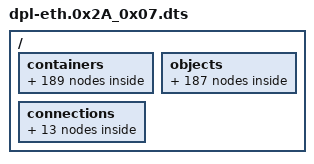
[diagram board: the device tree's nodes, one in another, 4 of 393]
/*
 * This DPL showcases one Linux configuration for SerDes 0x2a_07
 *
 * Copyright 2015 Freescale Semiconductor, Inc.
 */

/dts-v1/;
/ {
	/*****************************************************************
         * Containers
         *****************************************************************/
	containers {
		dprc@1 {
			compatible = "fsl,dprc";
			parent = "none";
			options = "DPRC_CFG_OPT_SPAWN_ALLOWED" , "DPRC_CFG_OPT_ALLOC_ALLOWED", "DPRC_CFG_OPT_IRQ_CFG_ALLOWED";

			objects {
				/* ------------- DPMACs --------------*/
				/* For SerDes 0x2a_07, 5 DPMACs are mapped
				 * on the 5 XFI ports and 8 DPMACs
				 * are mapped on the 8 SGMII ports of the PCIe
				 * Slot 4 riser card.
				 */
				obj@101 {
					obj_name = "dpmac@1";
				};
				obj@102 {
					obj_name = "dpmac@2";
				};
				obj@103 {
					obj_name = "dpmac@3";
				};
				obj@104 {
					obj_name = "dpmac@4";
				};
				obj@105 {
					obj_name = "dpmac@5";
				};

				obj@106 {
					obj_name = "dpmac@9";
				};
				obj@107 {
					obj_name = "dpmac@10";
				};
				obj@108 {
					obj_name = "dpmac@11";
				};
				obj@109 {
					obj_name = "dpmac@12";
				};
				obj@110 {
					obj_name = "dpmac@13";
				};
				obj@111 {
					obj_name = "dpmac@14";
				};
				obj@112 {
					obj_name = "dpmac@15";
				};
				obj@113 {
					obj_name = "dpmac@16";
				};

				/* ------------ DPNIs --------------*/
				obj@200 {
					obj_name="dpni@0";
				};
				obj@201 {
					obj_name="dpni@1";
				};
				obj@202 {
					obj_name="dpni@2";
				};
				obj@203 {
					obj_name="dpni@3";
				};
				obj@204 {
					obj_name="dpni@4";
				};
				obj@205 {
					obj_name="dpni@5";
				};
				obj@206 {
					obj_name="dpni@6";
				};
				obj@207 {
					obj_name="dpni@7";
				};
				obj@208 {
					obj_name="dpni@8";
				};
				obj@209 {
					obj_name="dpni@9";
				};
				obj@210 {
					obj_name="dpni@10";
				};
				obj@211 {
					obj_name="dpni@11";
				};
				obj@212 {
					obj_name="dpni@12";
				};

				/* ------------ DPBPs --------------*/
				/* Each DPNI uses one DPBP */
				obj@300 {
					obj_name="dpbp@0";
				};
				obj@301 {
					obj_name="dpbp@1";
				};
				obj@302 {
					obj_name="dpbp@2";
				};
				obj@303 {
					obj_name="dpbp@3";
				};
				obj@304 {
					obj_name="dpbp@4";
				};
				obj@305 {
					obj_name="dpbp@5";
				};
				obj@306 {
					obj_name="dpbp@6";
				};
				obj@307 {
					obj_name="dpbp@7";
				};
				obj@308 {
					obj_name="dpbp@8";
				};
				obj@309 {
					obj_name="dpbp@9";
				};
				obj@310 {
					obj_name="dpbp@10";
				};
				obj@311 {
					obj_name="dpbp@11";
				};
				obj@312 {
					obj_name="dpbp@12";
				};


				/* ------------ DPMCPs --------------*/
				/* Ethernet DPMCPs:
				*  One for every DPNI, one for every DPMAC, then
				*  one more for DPIO.
				*
				*  Next: DPRC and restool, VFIO and possibly
				*  others from the kernel have DPMCP requirements.
				*  We'll just add a slack of 10 MCPs.
				*/
				obj@501 {
					obj_name="dpmcp@1";
				};
				obj@502 {
					obj_name="dpmcp@2";
				};
				obj@503 {
					obj_name="dpmcp@3";
				};
				obj@504 {
					obj_name="dpmcp@4";
				};
				obj@505 {
					obj_name="dpmcp@5";
				};
				obj@506 {
					obj_name="dpmcp@6";
				};
				obj@507 {
					obj_name="dpmcp@7";
				};
				obj@508 {
					obj_name="dpmcp@8";
				};
				obj@509 {
					obj_name="dpmcp@9";
				};
				obj@510 {
					obj_name="dpmcp@10";
				};
				obj@511 {
					obj_name="dpmcp@11";
				};
				obj@512 {
					obj_name="dpmcp@12";
				};
				obj@513 {
					obj_name="dpmcp@13";
				};
				obj@514 {
					obj_name="dpmcp@14";
				};
				obj@515 {
					obj_name="dpmcp@15";
				};
				obj@516 {
					obj_name="dpmcp@16";
				};
				obj@517 {
					obj_name="dpmcp@17";
				};
				obj@518 {
					obj_name="dpmcp@18";
				};
				obj@519 {
					obj_name="dpmcp@19";
				};
				obj@520 {
					obj_name="dpmcp@20";
				};
				obj@521 {
					obj_name="dpmcp@21";
				};
				obj@522 {
					obj_name="dpmcp@22";
				};
				obj@523 {
					obj_name="dpmcp@23";
				};
				obj@524 {
					obj_name="dpmcp@24";
				};
				obj@525 {
					obj_name="dpmcp@25";
				};
				obj@526 {
					obj_name="dpmcp@26";
				};
				obj@527 {
					obj_name="dpmcp@27";
				};
				obj@528 {
					obj_name="dpmcp@28";
				};
				obj@529 {
					obj_name="dpmcp@29";
				};
				obj@530 {
					obj_name="dpmcp@30";
				};
				obj@531 {
					obj_name="dpmcp@31";
				};
				obj@532 {
					obj_name="dpmcp@32";
				};
				obj@533 {
					obj_name="dpmcp@33";
				};
				obj@534 {
					obj_name="dpmcp@34";
				};
				obj@535 {
					obj_name="dpmcp@35";
				};
				obj@536 {
					obj_name="dpmcp@36";
				};

				/* ------------ DPIOs --------------*/
				/* One DPIO for each online CPU. This is a
				 * maximal configuration.
				 */
				obj@400 {
					obj_name="dpio@0";
				};
				obj@401 {
					obj_name="dpio@1";
				};
				obj@402 {
					obj_name="dpio@2";
				};
				obj@403 {
					obj_name="dpio@3";
				};
				obj@404 {
					obj_name="dpio@4";
				};
				obj@405 {
					obj_name="dpio@5";
				};
				obj@406 {
					obj_name="dpio@6";
				};
				obj@407 {
					obj_name="dpio@7";
				};

				/* ------------ DPCONs --------------*/
				/* Used by DPNIs in Linux for CDAN-based dequeueing.
				 * Ideally, there should be one DPCON per {DPNIxDPIO}
				 * combination.
				 */
				obj@600 {
					obj_name="dpcon@0";
				};
				obj@601 {
					obj_name="dpcon@1";
				};
				obj@602 {
					obj_name="dpcon@2";
				};
				obj@603 {
					obj_name="dpcon@3";
				};
				obj@604 {
					obj_name="dpcon@4";
				};
				obj@605 {
					obj_name="dpcon@5";
				};
				obj@606 {
					obj_name="dpcon@6";
				};
				obj@607 {
					obj_name="dpcon@7";
				};
				obj@608 {
					obj_name="dpcon@8";
				};
				obj@609 {
					obj_name="dpcon@9";
				};
				obj@610 {
					obj_name="dpcon@10";
				};
				obj@611 {
					obj_name="dpcon@11";
				};
				obj@612 {
					obj_name="dpcon@12";
				};
				obj@613 {
					obj_name="dpcon@13";
				};
				obj@614 {
					obj_name="dpcon@14";
				};
				obj@615 {
					obj_name="dpcon@15";
				};
				obj@616 {
					obj_name="dpcon@16";
				};
				obj@617 {
					obj_name="dpcon@17";
				};
				obj@618 {
					obj_name="dpcon@18";
				};
				obj@619 {
					obj_name="dpcon@19";
				};
				obj@620 {
					obj_name="dpcon@20";
				};
				obj@621 {
					obj_name="dpcon@21";
				};
				obj@622 {
					obj_name="dpcon@22";
				};
				obj@623 {
					obj_name="dpcon@23";
				};
				obj@624 {
					obj_name="dpcon@24";
				};
				obj@625 {
					obj_name="dpcon@25";
				};
				obj@626 {
					obj_name="dpcon@26";
				};
				obj@627 {
					obj_name="dpcon@27";
				};
				obj@628 {
					obj_name="dpcon@28";
				};
				obj@629 {
					obj_name="dpcon@29";
				};
				obj@630 {
					obj_name="dpcon@30";
				};
				obj@631 {
					obj_name="dpcon@31";
				};
				obj@632 {
					obj_name="dpcon@32";
				};
				obj@633 {
					obj_name="dpcon@33";
				};
				obj@634 {
					obj_name="dpcon@34";
				};
				obj@635 {
					obj_name="dpcon@35";
				};
				obj@636 {
					obj_name="dpcon@36";
				};
				obj@637 {
					obj_name="dpcon@37";
				};
				obj@638 {
					obj_name="dpcon@38";
				};
				obj@639 {
					obj_name="dpcon@39";
				};
				obj@640 {
					obj_name="dpcon@40";
				};
				obj@641 {
					obj_name="dpcon@41";
				};
				obj@642 {
					obj_name="dpcon@42";
				};
				obj@643 {
					obj_name="dpcon@43";
				};
				obj@644 {
					obj_name="dpcon@44";
				};
				obj@645 {
					obj_name="dpcon@45";
				};
				obj@646 {
					obj_name="dpcon@46";
				};
				obj@647 {
					obj_name="dpcon@47";
				};
				obj@648 {
					obj_name="dpcon@48";
				};
				obj@649 {
					obj_name="dpcon@49";
				};
				obj@650 {
					obj_name="dpcon@50";
				};
				obj@651 {
					obj_name="dpcon@51";
				};
				obj@652 {
					obj_name="dpcon@52";
				};
				obj@653 {
					obj_name="dpcon@53";
				};
				obj@654 {
					obj_name="dpcon@54";
				};
				obj@655 {
					obj_name="dpcon@55";
				};
				obj@656 {
					obj_name="dpcon@56";
				};
				obj@657 {
					obj_name="dpcon@57";
				};
				obj@658 {
					obj_name="dpcon@58";
				};
				obj@659 {
					obj_name="dpcon@59";
				};
				obj@660 {
					obj_name="dpcon@60";
				};
				obj@661 {
					obj_name="dpcon@61";
				};
				obj@662 {
					obj_name="dpcon@62";
				};
				obj@663 {
					obj_name="dpcon@63";
				};
				obj@664 {
					obj_name="dpcon@64";
				};
				obj@665 {
					obj_name="dpcon@65";
				};
				obj@666 {
					obj_name="dpcon@66";
				};
				obj@667 {
					obj_name="dpcon@67";
				};
				obj@668 {
					obj_name="dpcon@68";
				};
				obj@669 {
					obj_name="dpcon@69";
				};
				obj@670 {
					obj_name="dpcon@70";
				};
				obj@671 {
					obj_name="dpcon@71";
				};
				obj@672 {
					obj_name="dpcon@72";
				};
				obj@673 {
					obj_name="dpcon@73";
				};
				obj@674 {
					obj_name="dpcon@74";
				};
				obj@675 {
					obj_name="dpcon@75";
				};
				obj@676 {
					obj_name="dpcon@76";
				};
				obj@677 {
					obj_name="dpcon@77";
				};
				obj@678 {
					obj_name="dpcon@78";
				};
				obj@679 {
					obj_name="dpcon@79";
				};
				obj@680 {
					obj_name="dpcon@80";
				};
				obj@681 {
					obj_name="dpcon@81";
				};
				obj@682 {
					obj_name="dpcon@82";
				};
				obj@683 {
					obj_name="dpcon@83";
				};
				obj@684 {
					obj_name="dpcon@84";
				};
				obj@685 {
					obj_name="dpcon@85";
				};
				obj@686 {
					obj_name="dpcon@86";
				};
				obj@687 {
					obj_name="dpcon@87";
				};
				obj@688 {
					obj_name="dpcon@88";
				};
				obj@689 {
					obj_name="dpcon@89";
				};
				obj@690 {
					obj_name="dpcon@90";
				};
				obj@691 {
					obj_name="dpcon@91";
				};
				obj@692 {
					obj_name="dpcon@92";
				};
				obj@693 {
					obj_name="dpcon@93";
				};
				obj@694 {
					obj_name="dpcon@94";
				};
				obj@695 {
					obj_name="dpcon@95";
				};
				obj@696 {
					obj_name="dpcon@96";
				};
				obj@697 {
					obj_name="dpcon@97";
				};
				obj@698 {
					obj_name="dpcon@98";
				};
				obj@699 {
					obj_name="dpcon@99";
				};
				obj@700 {
					obj_name="dpcon@100";
				};
				obj@701 {
					obj_name="dpcon@101";
				};
				obj@702 {
					obj_name="dpcon@102";
				};
				obj@703 {
					obj_name="dpcon@103";
				};
			};
		};
	};

	/*****************************************************************
         * Objects
         *****************************************************************/
	objects {

		/* ------------ DPBP --------------*/
		dpbp@0 {
			compatible="fsl,dpbp";
		};
		dpbp@1 {
			compatible="fsl,dpbp";
		};
		dpbp@2 {
			compatible="fsl,dpbp";
		};
		dpbp@3 {
			compatible="fsl,dpbp";
		};
		dpbp@4 {
			compatible="fsl,dpbp";
		};
		dpbp@5 {
			compatible="fsl,dpbp";
		};
		dpbp@6 {
			compatible="fsl,dpbp";
		};
		dpbp@7 {
			compatible="fsl,dpbp";
		};
		dpbp@8 {
			compatible="fsl,dpbp";
		};
		dpbp@9 {
			compatible="fsl,dpbp";
		};
		dpbp@10 {
			compatible="fsl,dpbp";
		};
		dpbp@11 {
			compatible="fsl,dpbp";
		};
		dpbp@12 {
			compatible="fsl,dpbp";
		};

		/* ------------ DPIO --------------*/
		dpio@0 {
			compatible="fsl,dpio";
			channel_mode="DPIO_LOCAL_CHANNEL";
			num_priorities=<8>;
		};
		dpio@1 {
			compatible="fsl,dpio";
			channel_mode="DPIO_LOCAL_CHANNEL";
			num_priorities=<8>;
		};
		dpio@2 {
			compatible="fsl,dpio";
			channel_mode="DPIO_LOCAL_CHANNEL";
			num_priorities=<8>;
		};
		dpio@3 {
			compatible="fsl,dpio";
			channel_mode="DPIO_LOCAL_CHANNEL";
			num_priorities=<8>;
		};
		dpio@4 {
			compatible="fsl,dpio";
			channel_mode="DPIO_LOCAL_CHANNEL";
			num_priorities=<8>;
		};
		dpio@5 {
			compatible="fsl,dpio";
			channel_mode="DPIO_LOCAL_CHANNEL";
			num_priorities=<8>;
		};
		dpio@6 {
			compatible="fsl,dpio";
			channel_mode="DPIO_LOCAL_CHANNEL";
			num_priorities=<8>;
		};
		dpio@7 {
			compatible="fsl,dpio";
			channel_mode="DPIO_LOCAL_CHANNEL";
			num_priorities=<8>;
		};

		/* ------------ DPCON --------------*/
		/* Use 2-WQ channels to accomodate the many DPNI needs */
		dpcon@0 {
			compatible="fsl,dpcon";
			num_priorities=<2>;
		};
		dpcon@1 {
			compatible="fsl,dpcon";
			num_priorities=<2>;
		};
		dpcon@2 {
			compatible="fsl,dpcon";
			num_priorities=<2>;
		};
		dpcon@3 {
			compatible="fsl,dpcon";
			num_priorities=<2>;
		};
		dpcon@4 {
			compatible="fsl,dpcon";
			num_priorities=<2>;
		};
		dpcon@5 {
			compatible="fsl,dpcon";
			num_priorities=<2>;
		};
		dpcon@6 {
			compatible="fsl,dpcon";
			num_priorities=<2>;
		};
		dpcon@7 {
			compatible="fsl,dpcon";
			num_priorities=<2>;
		};
		dpcon@8 {
			compatible="fsl,dpcon";
			num_priorities=<2>;
		};
		dpcon@9 {
			compatible="fsl,dpcon";
			num_priorities=<2>;
		};
		dpcon@10 {
			compatible="fsl,dpcon";
			num_priorities=<2>;
		};
		dpcon@11 {
			compatible="fsl,dpcon";
			num_priorities=<2>;
		};
		dpcon@12 {
			compatible="fsl,dpcon";
			num_priorities=<2>;
		};
		dpcon@13 {
			compatible="fsl,dpcon";
			num_priorities=<2>;
		};
		dpcon@14 {
			compatible="fsl,dpcon";
			num_priorities=<2>;
		};
		dpcon@15 {
			compatible="fsl,dpcon";
			num_priorities=<2>;
		};
		dpcon@16 {
			compatible="fsl,dpcon";
			num_priorities=<2>;
		};
		dpcon@17 {
			compatible="fsl,dpcon";
			num_priorities=<2>;
		};
		dpcon@18 {
			compatible="fsl,dpcon";
			num_priorities=<2>;
		};
		dpcon@19 {
			compatible="fsl,dpcon";
			num_priorities=<2>;
		};
		dpcon@20 {
			compatible="fsl,dpcon";
			num_priorities=<2>;
		};
		dpcon@21 {
			compatible="fsl,dpcon";
			num_priorities=<2>;
		};
		dpcon@22 {
			compatible="fsl,dpcon";
			num_priorities=<2>;
		};
		dpcon@23 {
			compatible="fsl,dpcon";
			num_priorities=<2>;
		};
		dpcon@24 {
			compatible="fsl,dpcon";
			num_priorities=<2>;
		};
		dpcon@25 {
			compatible="fsl,dpcon";
			num_priorities=<2>;
		};
		dpcon@26 {
			compatible="fsl,dpcon";
			num_priorities=<2>;
		};
		dpcon@27 {
			compatible="fsl,dpcon";
			num_priorities=<2>;
		};
		dpcon@28 {
			compatible="fsl,dpcon";
			num_priorities=<2>;
		};
		dpcon@29 {
			compatible="fsl,dpcon";
			num_priorities=<2>;
		};
		dpcon@30 {
			compatible="fsl,dpcon";
			num_priorities=<2>;
		};
		dpcon@31 {
			compatible="fsl,dpcon";
			num_priorities=<2>;
		};
		dpcon@32 {
			compatible="fsl,dpcon";
			num_priorities=<2>;
		};
		dpcon@33 {
			compatible="fsl,dpcon";
			num_priorities=<2>;
		};
		dpcon@34 {
			compatible="fsl,dpcon";
			num_priorities=<2>;
		};
		dpcon@35 {
			compatible="fsl,dpcon";
			num_priorities=<2>;
		};
		dpcon@36 {
			compatible="fsl,dpcon";
			num_priorities=<2>;
		};
		dpcon@37 {
			compatible="fsl,dpcon";
			num_priorities=<2>;
		};
		dpcon@38 {
			compatible="fsl,dpcon";
			num_priorities=<2>;
		};
		dpcon@39 {
			compatible="fsl,dpcon";
			num_priorities=<2>;
		};
		dpcon@40 {
			compatible="fsl,dpcon";
			num_priorities=<2>;
		};
		dpcon@41 {
			compatible="fsl,dpcon";
			num_priorities=<2>;
		};
		dpcon@42 {
			compatible="fsl,dpcon";
			num_priorities=<2>;
		};
		dpcon@43 {
			compatible="fsl,dpcon";
			num_priorities=<2>;
		};
		dpcon@44 {
			compatible="fsl,dpcon";
			num_priorities=<2>;
		};
		dpcon@45 {
			compatible="fsl,dpcon";
			num_priorities=<2>;
		};
		dpcon@46 {
			compatible="fsl,dpcon";
			num_priorities=<2>;
		};
		dpcon@47 {
			compatible="fsl,dpcon";
			num_priorities=<2>;
		};
		dpcon@48 {
			compatible="fsl,dpcon";
			num_priorities=<2>;
		};
		dpcon@49 {
			compatible="fsl,dpcon";
			num_priorities=<2>;
		};
		dpcon@50 {
			compatible="fsl,dpcon";
			num_priorities=<2>;
		};
		dpcon@51 {
			compatible="fsl,dpcon";
			num_priorities=<2>;
		};
		dpcon@52 {
			compatible="fsl,dpcon";
			num_priorities=<2>;
		};
		dpcon@53 {
			compatible="fsl,dpcon";
			num_priorities=<2>;
		};
		dpcon@54 {
			compatible="fsl,dpcon";
			num_priorities=<2>;
		};
		dpcon@55 {
			compatible="fsl,dpcon";
			num_priorities=<2>;
		};
		dpcon@56 {
			compatible="fsl,dpcon";
			num_priorities=<2>;
		};
		dpcon@57 {
			compatible="fsl,dpcon";
			num_priorities=<2>;
		};
		dpcon@58 {
			compatible="fsl,dpcon";
			num_priorities=<2>;
		};
		dpcon@59 {
			compatible="fsl,dpcon";
			num_priorities=<2>;
		};
		dpcon@60 {
			compatible="fsl,dpcon";
			num_priorities=<2>;
		};
		dpcon@61 {
			compatible="fsl,dpcon";
			num_priorities=<2>;
		};
		dpcon@62 {
			compatible="fsl,dpcon";
			num_priorities=<2>;
		};
		dpcon@63 {
			compatible="fsl,dpcon";
			num_priorities=<2>;
		};
		dpcon@64 {
			compatible="fsl,dpcon";
			num_priorities=<2>;
		};
		dpcon@65 {
			compatible="fsl,dpcon";
			num_priorities=<2>;
		};
		dpcon@66 {
			compatible="fsl,dpcon";
			num_priorities=<2>;
		};
		dpcon@67 {
			compatible="fsl,dpcon";
			num_priorities=<2>;
		};
		dpcon@68 {
			compatible="fsl,dpcon";
			num_priorities=<2>;
		};
		dpcon@69 {
			compatible="fsl,dpcon";
			num_priorities=<2>;
		};
		dpcon@70 {
			compatible="fsl,dpcon";
			num_priorities=<2>;
		};
		dpcon@71 {
			compatible="fsl,dpcon";
			num_priorities=<2>;
		};
		dpcon@72 {
			compatible="fsl,dpcon";
			num_priorities=<2>;
		};
		dpcon@73 {
			compatible="fsl,dpcon";
			num_priorities=<2>;
		};
		dpcon@74 {
			compatible="fsl,dpcon";
			num_priorities=<2>;
		};
		dpcon@75 {
			compatible="fsl,dpcon";
			num_priorities=<2>;
		};
		dpcon@76 {
			compatible="fsl,dpcon";
			num_priorities=<2>;
		};
		dpcon@77 {
			compatible="fsl,dpcon";
			num_priorities=<2>;
		};
		dpcon@78 {
			compatible="fsl,dpcon";
			num_priorities=<2>;
		};
		dpcon@79 {
			compatible="fsl,dpcon";
			num_priorities=<2>;
		};
		dpcon@80 {
			compatible="fsl,dpcon";
			num_priorities=<2>;
		};
		dpcon@81 {
			compatible="fsl,dpcon";
			num_priorities=<2>;
		};
		dpcon@82 {
			compatible="fsl,dpcon";
			num_priorities=<2>;
		};
		dpcon@83 {
			compatible="fsl,dpcon";
			num_priorities=<2>;
		};
		dpcon@84 {
			compatible="fsl,dpcon";
			num_priorities=<2>;
		};
		dpcon@85 {
			compatible="fsl,dpcon";
			num_priorities=<2>;
		};
		dpcon@86 {
			compatible="fsl,dpcon";
			num_priorities=<2>;
		};
		dpcon@87 {
			compatible="fsl,dpcon";
			num_priorities=<2>;
		};
		dpcon@88 {
			compatible="fsl,dpcon";
			num_priorities=<2>;
		};
		dpcon@89 {
			compatible="fsl,dpcon";
			num_priorities=<2>;
		};
		dpcon@90 {
			compatible="fsl,dpcon";
			num_priorities=<2>;
		};
		dpcon@91 {
			compatible="fsl,dpcon";
			num_priorities=<2>;
		};
		dpcon@92 {
			compatible="fsl,dpcon";
			num_priorities=<2>;
		};
		dpcon@93 {
			compatible="fsl,dpcon";
			num_priorities=<2>;
		};
		dpcon@94 {
			compatible="fsl,dpcon";
			num_priorities=<2>;
		};
		dpcon@95 {
			compatible="fsl,dpcon";
			num_priorities=<2>;
		};
		dpcon@96 {
			compatible="fsl,dpcon";
			num_priorities=<2>;
		};
		dpcon@97 {
			compatible="fsl,dpcon";
			num_priorities=<2>;
		};
		dpcon@98 {
			compatible="fsl,dpcon";
			num_priorities=<2>;
		};
		dpcon@99 {
			compatible="fsl,dpcon";
			num_priorities=<2>;
		};
		dpcon@100 {
			compatible="fsl,dpcon";
			num_priorities=<2>;
		};
		dpcon@101 {
			compatible="fsl,dpcon";
			num_priorities=<2>;
		};
		dpcon@102 {
			compatible="fsl,dpcon";
			num_priorities=<2>;
		};
		dpcon@103 {
			compatible="fsl,dpcon";
			num_priorities=<2>;
		};

		/* ------------ DPNI --------------*/
		dpni@0 {
			compatible="fsl,dpni";
			type = "DPNI_TYPE_NIC";
			mac_addr = <0x00 0x00 0x00 0x00 0x00 0x00>;
			max_senders = <8>;
			options = "DPNI_OPT_MULTICAST_FILTER", "DPNI_OPT_UNICAST_FILTER", "DPNI_OPT_DIST_HASH", "DPNI_OPT_DIST_FS";
			max_tcs = <1>;
			max_dist_per_tc = <8>;
			max_dist_key_size = <24>;
		};
		dpni@1 {
			compatible="fsl,dpni";
			type = "DPNI_TYPE_NIC";
			mac_addr = <0x00 0x00 0x00 0x00 0x00 0x00>;
			max_senders = <8>;
			options = "DPNI_OPT_MULTICAST_FILTER", "DPNI_OPT_UNICAST_FILTER", "DPNI_OPT_DIST_HASH", "DPNI_OPT_DIST_FS";
			max_tcs = <1>;
			max_dist_per_tc = <8>;
			max_dist_key_size = <24>;
		};
		dpni@2 {
			compatible="fsl,dpni";
			type = "DPNI_TYPE_NIC";
			mac_addr = <0x00 0x00 0x00 0x00 0x00 0x00>;
			max_senders = <8>;
			options = "DPNI_OPT_MULTICAST_FILTER", "DPNI_OPT_UNICAST_FILTER", "DPNI_OPT_DIST_HASH", "DPNI_OPT_DIST_FS";
			max_tcs = <1>;
			max_dist_per_tc = <8>;
			max_dist_key_size = <24>;
		};
		dpni@3 {
			compatible="fsl,dpni";
			type = "DPNI_TYPE_NIC";
			mac_addr = <0x00 0x00 0x00 0x00 0x00 0x00>;
			max_senders = <8>;
			options = "DPNI_OPT_MULTICAST_FILTER", "DPNI_OPT_UNICAST_FILTER", "DPNI_OPT_DIST_HASH", "DPNI_OPT_DIST_FS";
			max_tcs = <1>;
			max_dist_per_tc = <8>;
			max_dist_key_size = <24>;
		};
		dpni@4 {
			compatible="fsl,dpni";
			type = "DPNI_TYPE_NIC";
			mac_addr = <0x00 0x00 0x00 0x00 0x00 0x00>;
			max_senders = <8>;
			options = "DPNI_OPT_MULTICAST_FILTER", "DPNI_OPT_UNICAST_FILTER", "DPNI_OPT_DIST_HASH", "DPNI_OPT_DIST_FS";
			max_tcs = <1>;
			max_dist_per_tc = <8>;
			max_dist_key_size = <24>;
		};
		dpni@5 {
			compatible="fsl,dpni";
			type = "DPNI_TYPE_NIC";
			mac_addr = <0x00 0x00 0x00 0x00 0x00 0x00>;
			max_senders = <8>;
			options = "DPNI_OPT_MULTICAST_FILTER", "DPNI_OPT_UNICAST_FILTER", "DPNI_OPT_DIST_HASH", "DPNI_OPT_DIST_FS";
			max_tcs = <1>;
			max_dist_per_tc = <8>;
			max_dist_key_size = <24>;
		};
		dpni@6 {
			compatible="fsl,dpni";
			type = "DPNI_TYPE_NIC";
			mac_addr = <0x00 0x00 0x00 0x00 0x00 0x00>;
			max_senders = <8>;
			options = "DPNI_OPT_MULTICAST_FILTER", "DPNI_OPT_UNICAST_FILTER", "DPNI_OPT_DIST_HASH", "DPNI_OPT_DIST_FS";
			max_tcs = <1>;
			max_dist_per_tc = <8>;
			max_dist_key_size = <24>;
		};
		dpni@7 {
			compatible="fsl,dpni";
			type = "DPNI_TYPE_NIC";
			mac_addr = <0x00 0x00 0x00 0x00 0x00 0x00>;
			max_senders = <8>;
			options = "DPNI_OPT_MULTICAST_FILTER", "DPNI_OPT_UNICAST_FILTER", "DPNI_OPT_DIST_HASH", "DPNI_OPT_DIST_FS";
			max_tcs = <1>;
			max_dist_per_tc = <8>;
			max_dist_key_size = <24>;
		};
		dpni@8 {
			compatible="fsl,dpni";
			type = "DPNI_TYPE_NIC";
			mac_addr = <0x00 0x00 0x00 0x00 0x00 0x00>;
			max_senders = <8>;
			options = "DPNI_OPT_MULTICAST_FILTER", "DPNI_OPT_UNICAST_FILTER", "DPNI_OPT_DIST_HASH", "DPNI_OPT_DIST_FS";
			max_tcs = <1>;
			max_dist_per_tc = <8>;
			max_dist_key_size = <24>;
		};
		dpni@9 {
			compatible="fsl,dpni";
			type = "DPNI_TYPE_NIC";
			mac_addr = <0x00 0x00 0x00 0x00 0x00 0x00>;
			max_senders = <8>;
			options = "DPNI_OPT_MULTICAST_FILTER", "DPNI_OPT_UNICAST_FILTER", "DPNI_OPT_DIST_HASH", "DPNI_OPT_DIST_FS";
			max_tcs = <1>;
			max_dist_per_tc = <8>;
			max_dist_key_size = <24>;
		};
		dpni@10 {
			compatible="fsl,dpni";
			type = "DPNI_TYPE_NIC";
			mac_addr = <0x00 0x00 0x00 0x00 0x00 0x00>;
			max_senders = <8>;
			options = "DPNI_OPT_MULTICAST_FILTER", "DPNI_OPT_UNICAST_FILTER", "DPNI_OPT_DIST_HASH", "DPNI_OPT_DIST_FS";
			max_tcs = <1>;
			max_dist_per_tc = <8>;
			max_dist_key_size = <24>;
		};
		dpni@11 {
			compatible="fsl,dpni";
			type = "DPNI_TYPE_NIC";
			mac_addr = <0x00 0x00 0x00 0x00 0x00 0x00>;
			max_senders = <8>;
			options = "DPNI_OPT_MULTICAST_FILTER", "DPNI_OPT_UNICAST_FILTER", "DPNI_OPT_DIST_HASH", "DPNI_OPT_DIST_FS";
			max_tcs = <1>;
			max_dist_per_tc = <8>;
			max_dist_key_size = <24>;
		};
		dpni@12 {
			compatible="fsl,dpni";
			type = "DPNI_TYPE_NIC";
			mac_addr = <0x00 0x00 0x00 0x00 0x00 0x00>;
			max_senders = <8>;
			options = "DPNI_OPT_MULTICAST_FILTER", "DPNI_OPT_UNICAST_FILTER", "DPNI_OPT_DIST_HASH", "DPNI_OPT_DIST_FS";
			max_tcs = <1>;
			max_dist_per_tc = <8>;
			max_dist_key_size = <24>;
		};

		/* ------------ DPMAC --------------*/
		dpmac@1 {
			compatible = "fsl,dpmac";
		};
		dpmac@2 {
			compatible = "fsl,dpmac";
		};
		dpmac@3 {
			compatible = "fsl,dpmac";
		};
		dpmac@4 {
			compatible = "fsl,dpmac";
		};
		dpmac@5 {
			compatible = "fsl,dpmac";
		};

		dpmac@9 {
			compatible = "fsl,dpmac";
		};
		dpmac@10 {
			compatible = "fsl,dpmac";
		};
		dpmac@11 {
			compatible = "fsl,dpmac";
		};
		dpmac@12 {
			compatible = "fsl,dpmac";
		};
		dpmac@13 {
			compatible = "fsl,dpmac";
		};
		dpmac@14 {
			compatible = "fsl,dpmac";
		};
		dpmac@15 {
			compatible = "fsl,dpmac";
		};
		dpmac@16 {
			compatible = "fsl,dpmac";
		};

		/* ------------ DPMCP --------------*/
		dpmcp@1 {
			compatible="fsl,dpmcp";
		};
		dpmcp@2 {
			compatible="fsl,dpmcp";
		};
		dpmcp@3 {
			compatible="fsl,dpmcp";
		};
		dpmcp@4 {
			compatible="fsl,dpmcp";
		};
		dpmcp@5 {
			compatible="fsl,dpmcp";
		};
		dpmcp@6 {
			compatible="fsl,dpmcp";
		};
		dpmcp@7 {
			compatible="fsl,dpmcp";
		};
		dpmcp@8 {
			compatible="fsl,dpmcp";
		};
		dpmcp@9 {
			compatible="fsl,dpmcp";
		};
		dpmcp@10 {
			compatible="fsl,dpmcp";
		};
		dpmcp@11 {
			compatible="fsl,dpmcp";
		};
		dpmcp@12 {
			compatible="fsl,dpmcp";
		};
		dpmcp@13 {
			compatible="fsl,dpmcp";
		};
		dpmcp@14 {
			compatible="fsl,dpmcp";
		};
		dpmcp@15 {
			compatible="fsl,dpmcp";
		};
		dpmcp@16 {
			compatible="fsl,dpmcp";
		};
		dpmcp@17 {
			compatible="fsl,dpmcp";
		};
		dpmcp@18 {
			compatible="fsl,dpmcp";
		};
		dpmcp@19 {
			compatible="fsl,dpmcp";
		};
		dpmcp@20 {
			compatible="fsl,dpmcp";
		};
		dpmcp@21 {
			compatible="fsl,dpmcp";
		};
		dpmcp@22 {
			compatible="fsl,dpmcp";
		};
		dpmcp@23 {
			compatible="fsl,dpmcp";
		};
		dpmcp@24 {
			compatible="fsl,dpmcp";
		};
		dpmcp@25 {
			compatible="fsl,dpmcp";
		};
		dpmcp@26 {
			compatible="fsl,dpmcp";
		};
		dpmcp@27 {
			compatible="fsl,dpmcp";
		};
		dpmcp@28 {
			compatible="fsl,dpmcp";
		};
		dpmcp@29 {
			compatible="fsl,dpmcp";
		};
		dpmcp@30 {
			compatible="fsl,dpmcp";
		};
		dpmcp@31 {
			compatible="fsl,dpmcp";
		};
		dpmcp@32 {
			compatible="fsl,dpmcp";
		};
		dpmcp@33 {
			compatible="fsl,dpmcp";
		};
		dpmcp@34 {
			compatible="fsl,dpmcp";
		};
		dpmcp@35 {
			compatible="fsl,dpmcp";
		};
		dpmcp@36 {
			compatible="fsl,dpmcp";
		};
	};

	/*****************************************************************
         * Connections
         *****************************************************************/
	connections {
		/* XFIs */
		connection@1{
			endpoint1 = "dpni@0";
			endpoint2 = "dpmac@1";
		};
		connection@2{
			endpoint1 = "dpni@1";
			endpoint2 = "dpmac@2";
		};
		connection@3{
			endpoint1 = "dpni@2";
			endpoint2 = "dpmac@3";
		};
		connection@4{
			endpoint1 = "dpni@3";
			endpoint2 = "dpmac@4";
		};
		connection@5{
			endpoint1 = "dpni@4";
			endpoint2 = "dpmac@5";
		};
		/* SGMIIs */
		connection@6{
			endpoint1 = "dpni@5";
			endpoint2 = "dpmac@9";
		};
		connection@7{
			endpoint1 = "dpni@6";
			endpoint2 = "dpmac@10";
		};
		connection@8{
			endpoint1 = "dpni@7";
			endpoint2 = "dpmac@11";
		};
		connection@9{
			endpoint1 = "dpni@8";
			endpoint2 = "dpmac@12";
		};
		connection@10{
			endpoint1 = "dpni@9";
			endpoint2 = "dpmac@13";
		};
		connection@11{
			endpoint1 = "dpni@10";
			endpoint2 = "dpmac@14";
		};
		connection@12{
			endpoint1 = "dpni@11";
			endpoint2 = "dpmac@15";
		};
		connection@13{
			endpoint1 = "dpni@12";
			endpoint2 = "dpmac@16";
		};
	};
};
